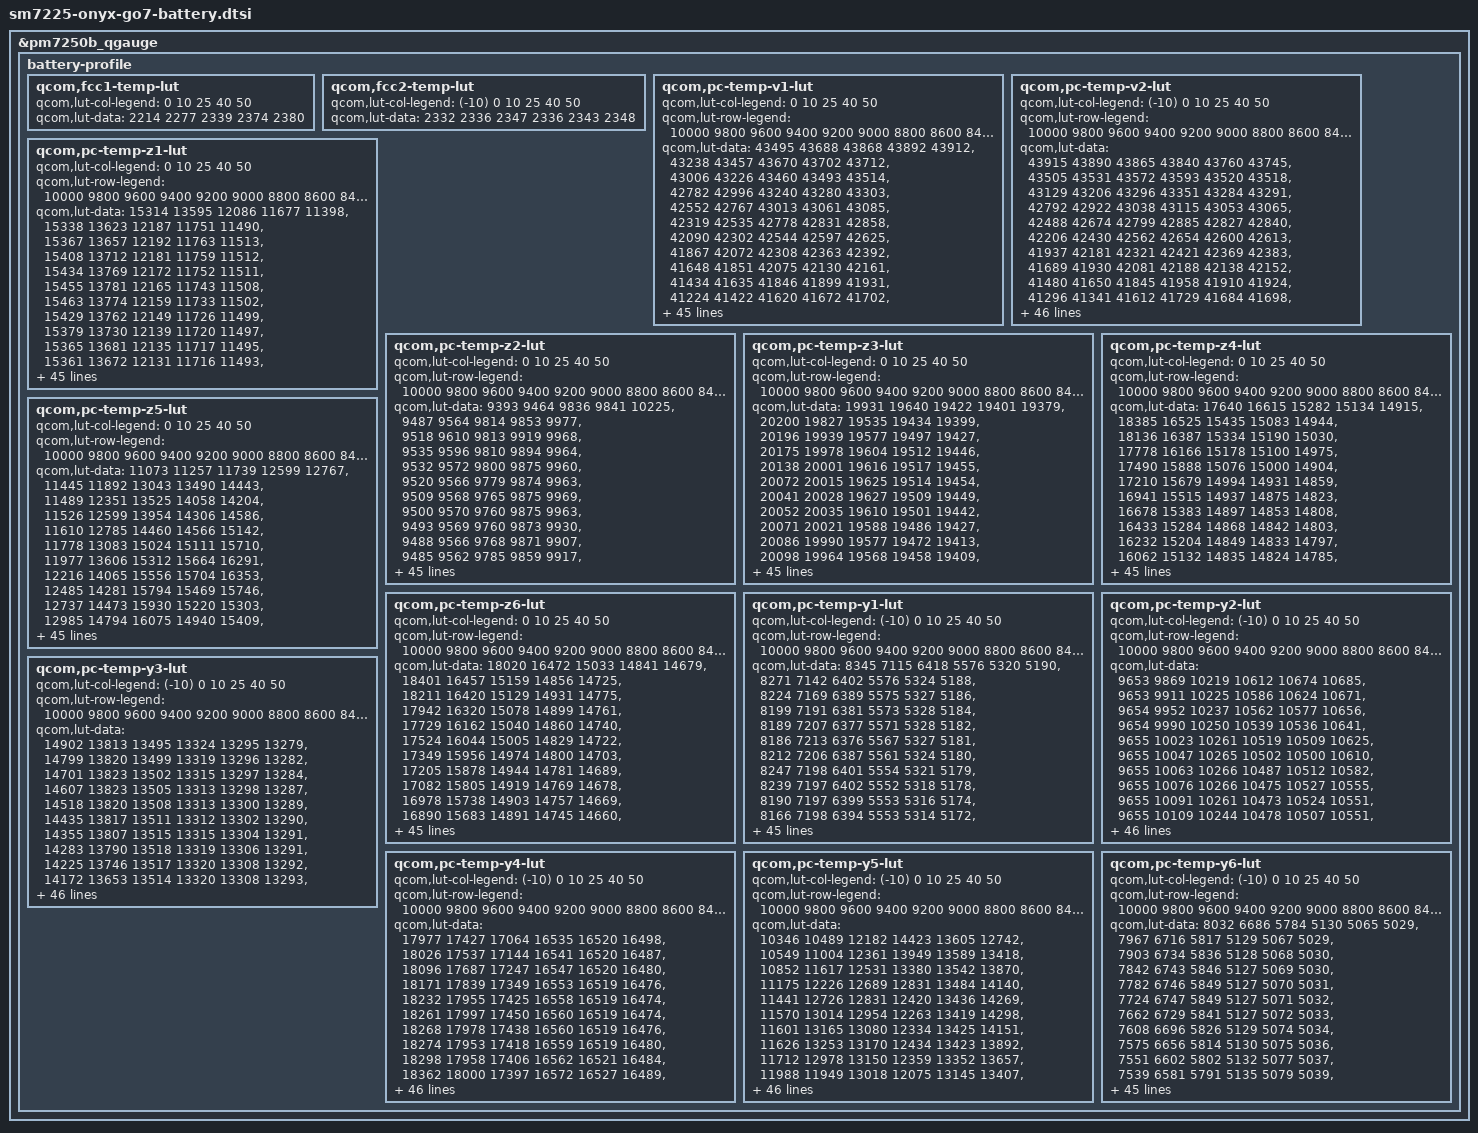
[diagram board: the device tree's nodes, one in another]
// SPDX-License-Identifier: BSD-3-Clause

&pm7250b_qgauge {
	battery-profile {
		qcom,fcc1-temp-lut {
			qcom,lut-col-legend = <0 10 25 40 50>;
			qcom,lut-data = <2214 2277 2339 2374 2380>;
		};

		qcom,fcc2-temp-lut {
			qcom,lut-col-legend = <(-10) 0 10 25 40 50>;
			qcom,lut-data = <2332 2336 2347 2336 2343 2348>;
		};

		qcom,pc-temp-v1-lut {
			qcom,lut-col-legend = <0 10 25 40 50>;
			qcom,lut-row-legend = <10000 9800 9600 9400 9200 9000 8800 8600 8400 8200
						8000 7800 7600 7400 7200 7000 6800 6600 6400 6200
						6000 5800 5600 5400 5200 5000 4800 4600 4400 4200
						4000 3800 3600 3400 3200 3000 2800 2600 2400 2200
						2000 1800 1600 1400 1200 1000 900 800 700 600 500
						400 300 200 100 0>;
			qcom,lut-data = <43495 43688 43868 43892 43912>,
					<43238 43457 43670 43702 43712>,
					<43006 43226 43460 43493 43514>,
					<42782 42996 43240 43280 43303>,
					<42552 42767 43013 43061 43085>,
					<42319 42535 42778 42831 42858>,
					<42090 42302 42544 42597 42625>,
					<41867 42072 42308 42363 42392>,
					<41648 41851 42075 42130 42161>,
					<41434 41635 41846 41899 41931>,
					<41224 41422 41620 41672 41702>,
					<41020 41211 41400 41449 41476>,
					<40825 41005 41183 41229 41256>,
					<40637 40810 40975 41015 41042>,
					<40450 40621 40773 40808 40834>,
					<40258 40434 40578 40608 40631>,
					<40078 40250 40393 40416 40436>,
					<39922 40074 40217 40235 40252>,
					<39783 39914 40046 40062 40076>,
					<39649 39765 39885 39889 39902>,
					<39520 39614 39721 39723 39733>,
					<39396 39461 39510 39542 39554>,
					<39273 39300 39219 39305 39331>,
					<39152 39098 38991 39065 39097>,
					<39035 38868 38873 38907 38927>,
					<38920 38706 38784 38792 38798>,
					<38809 38604 38687 38686 38684>,
					<38704 38528 38587 38580 38577>,
					<38603 38475 38495 38484 38480>,
					<38512 38435 38410 38396 38389>,
					<38440 38396 38334 38318 38305>,
					<38378 38357 38266 38249 38229>,
					<38329 38319 38205 38190 38161>,
					<38293 38284 38151 38134 38098>,
					<38262 38252 38106 38082 38040>,
					<38230 38217 38063 38031 37984>,
					<38200 38182 38021 37976 37919>,
					<38162 38140 37979 37916 37845>,
					<38105 38072 37921 37845 37763>,
					<38028 37962 37830 37758 37677>,
					<37929 37840 37720 37655 37579>,
					<37785 37717 37604 37537 37465>,
					<37633 37580 37471 37400 37329>,
					<37474 37417 37309 37241 37172>,
					<37358 37271 37165 37098 37032>,
					<37254 37178 37077 37016 36954>,
					<37214 37147 37056 36996 36933>,
					<37178 37124 37039 36979 36919>,
					<37142 37101 37018 36960 36901>,
					<37089 37057 36976 36901 36841>,
					<36920 36868 36756 36649 36557>,
					<36502 36446 36340 36241 36140>,
					<35943 35891 35782 35691 35591>,
					<35188 35137 35024 34942 34832>,
					<33993 33976 33864 33801 33677>,
					<30000 30000 30000 30000 30000>;
		};

		qcom,pc-temp-v2-lut {
			qcom,lut-col-legend = <(-10) 0 10 25 40 50>;
			qcom,lut-row-legend = <10000 9800 9600 9400 9200 9000 8800 8600 8400 8200
						8000 7800 7600 7400 7200 7000 6800 6600 6400 6200
						6000 5800 5600 5400 5200 5000 4800 4600 4400 4200
						4000 3800 3600 3400 3200 3000 2800 2600 2400 2200
						2000 1800 1600 1400 1200 1000 900 800 700 600 500
						400 300 200 100 0>;
			qcom,lut-data = <43915 43890 43865 43840 43760 43745>,
					<43505 43531 43572 43593 43520 43518>,
					<43129 43206 43296 43351 43284 43291>,
					<42792 42922 43038 43115 43053 43065>,
					<42488 42674 42799 42885 42827 42840>,
					<42206 42430 42562 42654 42600 42613>,
					<41937 42181 42321 42421 42369 42383>,
					<41689 41930 42081 42188 42138 42152>,
					<41480 41650 41845 41958 41910 41924>,
					<41296 41341 41612 41729 41684 41698>,
					<41131 41136 41381 41505 41462 41475>,
					<40997 41050 41140 41288 41244 41256>,
					<40850 40968 40918 41074 41029 41040>,
					<40569 40769 40746 40865 40824 40834>,
					<40122 40423 40601 40660 40624 40633>,
					<39792 40123 40430 40464 40430 40439>,
					<39609 39897 40221 40277 40242 40251>,
					<39450 39686 39996 40095 40060 40068>,
					<39252 39463 39755 39922 39888 39897>,
					<39040 39239 39505 39754 39721 39730>,
					<38844 39034 39279 39555 39521 39529>,
					<38656 38849 39074 39291 39255 39272>,
					<38499 38673 38888 39045 39018 39041>,
					<38391 38483 38725 38873 38859 38880>,
					<38309 38301 38577 38732 38729 38746>,
					<38235 38192 38439 38608 38610 38625>,
					<38172 38128 38309 38496 38501 38516>,
					<38111 38076 38193 38395 38401 38415>,
					<38051 38027 38082 38301 38309 38322>,
					<37992 37984 37987 38214 38224 38234>,
					<37933 37938 37926 38135 38147 38156>,
					<37874 37890 37882 38062 38076 38083>,
					<37813 37841 37841 37992 38005 38011>,
					<37747 37792 37801 37926 37935 37943>,
					<37677 37742 37761 37863 37860 37870>,
					<37607 37688 37716 37792 37770 37769>,
					<37537 37630 37668 37717 37664 37644>,
					<37466 37567 37611 37638 37563 37531>,
					<37392 37498 37539 37561 37474 37436>,
					<37317 37419 37455 37481 37384 37343>,
					<37246 37324 37353 37389 37290 37248>,
					<37178 37211 37233 37285 37189 37146>,
					<37105 37086 37085 37169 37065 37026>,
					<37028 36960 36936 37032 36926 36885>,
					<36943 36857 36819 36901 36836 36802>,
					<36843 36782 36738 36869 36819 36782>,
					<36784 36748 36706 36854 36802 36765>,
					<36715 36718 36670 36838 36776 36744>,
					<36620 36673 36611 36805 36711 36682>,
					<36472 36568 36487 36703 36494 36472>,
					<36207 36300 36219 36410 36113 36092>,
					<35795 35835 35764 35942 35615 35591>,
					<35187 35197 35136 35326 34964 34942>,
					<34322 34323 34257 34512 34110 34081>,
					<33006 32950 32909 33355 32852 32869>,
					<30300 30329 30466 30054 30346 30226>;
		};

		qcom,pc-temp-z1-lut {
			qcom,lut-col-legend = <0 10 25 40 50>;
			qcom,lut-row-legend = <10000 9800 9600 9400 9200 9000 8800 8600 8400 8200
						8000 7800 7600 7400 7200 7000 6800 6600 6400 6200
						6000 5800 5600 5400 5200 5000 4800 4600 4400 4200
						4000 3800 3600 3400 3200 3000 2800 2600 2400 2200
						2000 1800 1600 1400 1200 1000 900 800 700 600 500
						400 300 200 100 0>;
			qcom,lut-data = <15314 13595 12086 11677 11398>,
					<15338 13623 12187 11751 11490>,
					<15367 13657 12192 11763 11513>,
					<15408 13712 12181 11759 11512>,
					<15434 13769 12172 11752 11511>,
					<15455 13781 12165 11743 11508>,
					<15463 13774 12159 11733 11502>,
					<15429 13762 12149 11726 11499>,
					<15379 13730 12139 11720 11497>,
					<15365 13681 12135 11717 11495>,
					<15361 13672 12131 11716 11493>,
					<15352 13701 12131 11716 11492>,
					<15327 13727 12134 11714 11491>,
					<15293 13716 12137 11712 11491>,
					<15263 13692 12135 11711 11492>,
					<15238 13688 12131 11712 11494>,
					<15211 13727 12130 11714 11496>,
					<15161 13762 12132 11716 11496>,
					<15087 13756 12135 11719 11496>,
					<15051 13740 12141 11722 11497>,
					<15065 13735 12151 11724 11499>,
					<15091 13749 12157 11727 11502>,
					<15111 13766 12162 11732 11505>,
					<15135 13770 12168 11739 11509>,
					<15158 13766 12178 11744 11512>,
					<15181 13769 12188 11749 11516>,
					<15203 13796 12196 11754 11520>,
					<15210 13822 12203 11763 11525>,
					<15210 13823 12210 11772 11531>,
					<15209 13819 12228 11777 11536>,
					<15201 13816 12245 11782 11541>,
					<15179 13828 12246 11786 11546>,
					<15168 13846 12241 11791 11550>,
					<15164 13857 12239 11796 11555>,
					<15164 13871 12247 11805 11560>,
					<15197 13881 12258 11815 11566>,
					<15300 13883 12267 11820 11570>,
					<15372 13883 12277 11822 11573>,
					<15377 13891 12288 11825 11576>,
					<15367 13910 12302 11830 11579>,
					<15342 13924 12313 11835 11582>,
					<15266 13948 12313 11841 11586>,
					<15247 13965 12310 11847 11590>,
					<15343 13948 12315 11854 11593>,
					<15307 13921 12329 11864 11599>,
					<15201 13940 12333 11880 11604>,
					<15247 13944 12351 11884 11606>,
					<15301 13924 12343 11886 11608>,
					<15208 13909 12338 11890 11610>,
					<15211 13964 12363 11893 11614>,
					<15228 13944 12378 11898 11621>,
					<15216 13980 12379 11909 11630>,
					<15258 14028 12400 11927 11641>,
					<15295 14050 12450 11948 11660>,
					<15295 14050 12450 11948 11660>,
					<15295 14050 12450 11948 11660>;
		};

		qcom,pc-temp-z2-lut {
			qcom,lut-col-legend = <0 10 25 40 50>;
			qcom,lut-row-legend = <10000 9800 9600 9400 9200 9000 8800 8600 8400 8200
						8000 7800 7600 7400 7200 7000 6800 6600 6400 6200
						6000 5800 5600 5400 5200 5000 4800 4600 4400 4200
						4000 3800 3600 3400 3200 3000 2800 2600 2400 2200
						2000 1800 1600 1400 1200 1000 900 800 700 600 500
						400 300 200 100 0>;
			qcom,lut-data = <9393 9464 9836 9841 10225>,
					<9487 9564 9814 9853 9977>,
					<9518 9610 9813 9919 9968>,
					<9535 9596 9810 9894 9964>,
					<9532 9572 9800 9875 9960>,
					<9520 9566 9779 9874 9963>,
					<9509 9568 9765 9875 9969>,
					<9500 9570 9760 9875 9963>,
					<9493 9569 9760 9873 9930>,
					<9488 9566 9768 9871 9907>,
					<9485 9562 9785 9859 9917>,
					<9482 9555 9795 9846 9937>,
					<9480 9548 9802 9843 9945>,
					<9477 9543 9808 9842 9956>,
					<9474 9539 9817 9846 9965>,
					<9468 9538 9828 9854 9978>,
					<9463 9543 9835 9863 9990>,
					<9465 9551 9841 9876 9993>,
					<9469 9563 9845 9893 9991>,
					<9472 9580 9829 9899 9989>,
					<9467 9598 9804 9902 9987>,
					<9462 9616 9803 9902 9987>,
					<9461 9631 9822 9879 9988>,
					<9463 9638 9835 9850 9990>,
					<9466 9642 9837 9866 10001>,
					<9469 9648 9838 9937 10038>,
					<9475 9657 9836 9968 10057>,
					<9481 9665 9828 9941 9993>,
					<9491 9666 9820 9911 9915>,
					<9501 9666 9811 9907 9911>,
					<9505 9667 9804 9907 9921>,
					<9509 9672 9808 9909 9929>,
					<9511 9678 9829 9914 9936>,
					<9511 9683 9847 9921 9946>,
					<9512 9687 9864 9946 9973>,
					<9514 9691 9878 9984 10021>,
					<9517 9696 9882 10006 10049>,
					<9521 9702 9884 10020 10082>,
					<9535 9708 9889 10029 10097>,
					<9555 9715 9908 10033 10119>,
					<9570 9718 9923 10036 10147>,
					<9579 9711 9918 10029 10130>,
					<9589 9705 9912 10007 10085>,
					<9601 9707 9908 9994 10075>,
					<9303 9738 9914 9985 10080>,
					<9226 9745 9899 9998 10106>,
					<9240 9744 9898 9968 10072>,
					<9257 9701 9919 9957 10076>,
					<9277 9674 9936 9991 10105>,
					<9260 9683 9889 9994 10135>,
					<9253 9688 9964 9948 10023>,
					<9213 9602 9946 9922 9984>,
					<9159 9555 9899 9913 9953>,
					<9106 9494 9877 9861 9899>,
					<9106 9494 9877 9861 9899>,
					<9106 9494 9877 9861 9899>;
		};

		qcom,pc-temp-z3-lut {
			qcom,lut-col-legend = <0 10 25 40 50>;
			qcom,lut-row-legend = <10000 9800 9600 9400 9200 9000 8800 8600 8400 8200
						8000 7800 7600 7400 7200 7000 6800 6600 6400 6200
						6000 5800 5600 5400 5200 5000 4800 4600 4400 4200
						4000 3800 3600 3400 3200 3000 2800 2600 2400 2200
						2000 1800 1600 1400 1200 1000 900 800 700 600 500
						400 300 200 100 0>;
			qcom,lut-data = <19931 19640 19422 19401 19379>,
					<20200 19827 19535 19434 19399>,
					<20196 19939 19577 19497 19427>,
					<20175 19978 19604 19512 19446>,
					<20138 20001 19616 19517 19455>,
					<20072 20015 19625 19514 19454>,
					<20041 20028 19627 19509 19449>,
					<20052 20035 19610 19501 19442>,
					<20071 20021 19588 19486 19427>,
					<20086 19990 19577 19472 19413>,
					<20098 19964 19568 19458 19409>,
					<20106 19942 19560 19447 19405>,
					<20109 19924 19549 19442 19397>,
					<20110 19912 19540 19438 19384>,
					<20110 19900 19533 19435 19378>,
					<20109 19886 19526 19432 19378>,
					<20106 19863 19521 19430 19377>,
					<20097 19841 19511 19427 19376>,
					<20077 19833 19504 19425 19375>,
					<20069 19826 19506 19425 19375>,
					<20073 19823 19511 19426 19380>,
					<20081 19818 19520 19426 19385>,
					<20092 19815 19539 19425 19381>,
					<20118 19821 19550 19422 19375>,
					<20142 19835 19534 19425 19381>,
					<20159 19841 19512 19436 19414>,
					<20174 19838 19514 19450 19432>,
					<20177 19833 19542 19472 19427>,
					<20176 19825 19559 19490 19419>,
					<20174 19815 19560 19489 19413>,
					<20169 19807 19561 19483 19407>,
					<20158 19803 19559 19475 19401>,
					<20144 19800 19552 19463 19395>,
					<20127 19798 19546 19453 19390>,
					<20106 19795 19540 19449 19388>,
					<20082 19792 19535 19446 19387>,
					<20052 19784 19532 19445 19386>,
					<20022 19774 19529 19443 19386>,
					<19990 19768 19526 19442 19385>,
					<19959 19762 19523 19440 19385>,
					<19944 19758 19518 19436 19384>,
					<19938 19753 19513 19433 19383>,
					<19926 19745 19507 19429 19382>,
					<19891 19726 19503 19425 19380>,
					<19404 19674 19489 19417 19373>,
					<19289 19619 19472 19405 19361>,
					<19286 19609 19461 19405 19362>,
					<19284 19530 19452 19398 19356>,
					<19280 19444 19450 19392 19352>,
					<19282 19429 19452 19391 19359>,
					<19283 19469 19445 19419 19387>,
					<19289 19439 19445 19413 19390>,
					<19302 19422 19435 19419 19387>,
					<19343 19430 19438 19418 19392>,
					<19343 19430 19438 19418 19392>,
					<19343 19430 19438 19418 19392>;
		};

		qcom,pc-temp-z4-lut {
			qcom,lut-col-legend = <0 10 25 40 50>;
			qcom,lut-row-legend = <10000 9800 9600 9400 9200 9000 8800 8600 8400 8200
						8000 7800 7600 7400 7200 7000 6800 6600 6400 6200
						6000 5800 5600 5400 5200 5000 4800 4600 4400 4200
						4000 3800 3600 3400 3200 3000 2800 2600 2400 2200
						2000 1800 1600 1400 1200 1000 900 800 700 600 500
						400 300 200 100 0>;
			qcom,lut-data = <17640 16615 15282 15134 14915>,
					<18385 16525 15435 15083 14944>,
					<18136 16387 15334 15190 15030>,
					<17778 16166 15178 15100 14975>,
					<17490 15888 15076 15000 14904>,
					<17210 15679 14994 14931 14859>,
					<16941 15515 14937 14875 14823>,
					<16678 15383 14897 14853 14808>,
					<16433 15284 14868 14842 14803>,
					<16232 15204 14849 14833 14797>,
					<16062 15132 14835 14824 14785>,
					<15917 15062 14824 14815 14771>,
					<15793 15009 14814 14804 14762>,
					<15687 14977 14807 14791 14755>,
					<15604 14953 14799 14778 14748>,
					<15545 14945 14790 14767 14735>,
					<15489 14943 14785 14757 14722>,
					<15418 14941 14782 14747 14711>,
					<15338 14924 14780 14738 14700>,
					<15274 14889 14778 14737 14698>,
					<15232 14878 14776 14744 14703>,
					<15195 14885 14801 14758 14712>,
					<15153 14902 14954 14859 14790>,
					<15106 14971 15054 14988 14911>,
					<15070 15115 15039 14996 14922>,
					<15049 15171 15007 14958 14868>,
					<15033 15170 14966 14915 14822>,
					<15031 15168 14903 14866 14801>,
					<15043 15155 14857 14824 14785>,
					<15054 15115 14830 14804 14770>,
					<15057 15079 14812 14792 14756>,
					<15059 15051 14806 14787 14746>,
					<15059 15026 14802 14786 14737>,
					<15049 15003 14801 14785 14733>,
					<15031 14981 14804 14788 14735>,
					<15015 14962 14807 14797 14743>,
					<14999 14939 14810 14810 14757>,
					<14981 14921 14813 14830 14784>,
					<14961 14922 14817 14840 14798>,
					<14940 14935 14822 14838 14795>,
					<14929 14941 14825 14833 14788>,
					<14923 14920 14814 14821 14776>,
					<14914 14889 14793 14802 14762>,
					<14893 14869 14783 14795 14763>,
					<15247 14816 14759 14781 14760>,
					<15332 14797 14717 14723 14722>,
					<15319 14791 14710 14713 14700>,
					<15311 14860 14698 14693 14681>,
					<15300 14936 14679 14681 14667>,
					<15287 14940 14692 14695 14679>,
					<15285 14909 14716 14703 14685>,
					<15334 14983 14722 14703 14675>,
					<15375 15017 14733 14692 14670>,
					<15406 15035 14735 14696 14669>,
					<15406 15035 14735 14696 14669>,
					<15406 15035 14735 14696 14669>;
		};

		qcom,pc-temp-z5-lut {
			qcom,lut-col-legend = <0 10 25 40 50>;
			qcom,lut-row-legend = <10000 9800 9600 9400 9200 9000 8800 8600 8400 8200
						8000 7800 7600 7400 7200 7000 6800 6600 6400 6200
						6000 5800 5600 5400 5200 5000 4800 4600 4400 4200
						4000 3800 3600 3400 3200 3000 2800 2600 2400 2200
						2000 1800 1600 1400 1200 1000 900 800 700 600 500
						400 300 200 100 0>;
			qcom,lut-data = <11073 11257 11739 12599 12767>,
					<11445 11892 13043 13490 14443>,
					<11489 12351 13525 14058 14204>,
					<11526 12599 13954 14306 14586>,
					<11610 12785 14460 14566 15142>,
					<11778 13083 15024 15111 15710>,
					<11977 13606 15312 15664 16291>,
					<12216 14065 15556 15704 16353>,
					<12485 14281 15794 15469 15746>,
					<12737 14473 15930 15220 15303>,
					<12985 14794 16075 14940 15409>,
					<13215 15429 16175 14726 15592>,
					<13424 16047 16225 14791 15487>,
					<13614 16575 16234 15051 14995>,
					<13776 17173 16308 15310 14788>,
					<13926 17383 16534 15593 15143>,
					<14040 17244 16611 15927 15719>,
					<14105 17126 16512 16413 16215>,
					<14160 17748 16515 17012 16752>,
					<14222 19450 17123 17423 17551>,
					<14363 21084 18347 18031 19089>,
					<14613 22567 19732 18355 20078>,
					<15076 24198 21678 17492 18052>,
					<16163 26489 22692 16084 14614>,
					<17554 29228 19884 15266 14072>,
					<19281 30103 15715 14574 14677>,
					<21340 28573 15201 14380 15201>,
					<23122 26379 16043 15644 15442>,
					<24945 24650 17139 17515 15700>,
					<26125 22992 18591 19013 16164>,
					<26209 22384 20233 20441 16976>,
					<26152 22370 21654 21331 17883>,
					<26018 22386 23076 21832 18943>,
					<25295 22635 24035 22306 19951>,
					<24156 23423 24817 23072 20833>,
					<23055 24034 25341 23807 21546>,
					<21783 24562 25225 23730 21383>,
					<20891 25198 24717 22617 19881>,
					<20451 25857 24117 21449 18724>,
					<20126 26646 23220 20341 18270>,
					<20221 26990 22391 19455 17964>,
					<21462 26250 21947 19183 17924>,
					<21884 25176 21604 19030 17939>,
					<20339 23480 21051 18287 17152>,
					<12265 22340 20914 17839 16386>,
					<10532 19121 21549 19795 16732>,
					<10509 17909 19917 19994 18257>,
					<10477 15260 18828 20968 19341>,
					<10465 11843 20641 21241 21252>,
					<10465 11699 19461 19768 20197>,
					<10484 12343 16567 21274 22036>,
					<10490 11582 15809 18588 22249>,
					<10415 11262 14742 19081 20803>,
					<10403 11149 14553 18047 21655>,
					<10403 11149 14553 18047 21655>,
					<10403 11149 14553 18047 21655>;
		};

		qcom,pc-temp-z6-lut {
			qcom,lut-col-legend = <0 10 25 40 50>;
			qcom,lut-row-legend = <10000 9800 9600 9400 9200 9000 8800 8600 8400 8200
						8000 7800 7600 7400 7200 7000 6800 6600 6400 6200
						6000 5800 5600 5400 5200 5000 4800 4600 4400 4200
						4000 3800 3600 3400 3200 3000 2800 2600 2400 2200
						2000 1800 1600 1400 1200 1000 900 800 700 600 500
						400 300 200 100 0>;
			qcom,lut-data = <18020 16472 15033 14841 14679>,
					<18401 16457 15159 14856 14725>,
					<18211 16420 15129 14931 14775>,
					<17942 16320 15078 14899 14761>,
					<17729 16162 15040 14860 14740>,
					<17524 16044 15005 14829 14722>,
					<17349 15956 14974 14800 14703>,
					<17205 15878 14944 14781 14689>,
					<17082 15805 14919 14769 14678>,
					<16978 15738 14903 14757 14669>,
					<16890 15683 14891 14745 14660>,
					<16811 15635 14880 14734 14652>,
					<16738 15599 14870 14725 14643>,
					<16671 15578 14862 14717 14634>,
					<16614 15563 14854 14710 14626>,
					<16568 15550 14847 14703 14620>,
					<16525 15540 14841 14698 14615>,
					<16472 15529 14834 14692 14609>,
					<16414 15517 14831 14688 14604>,
					<16386 15505 14832 14688 14603>,
					<16380 15501 14835 14691 14607>,
					<16376 15506 14853 14699 14615>,
					<16376 15516 14931 14743 14649>,
					<16380 15552 14981 14798 14698>,
					<16384 15626 14969 14803 14707>,
					<16390 15656 14948 14795 14701>,
					<16398 15657 14934 14787 14694>,
					<16406 15658 14923 14779 14684>,
					<16418 15652 14914 14771 14673>,
					<16427 15634 14908 14763 14663>,
					<16428 15618 14902 14756 14655>,
					<16429 15607 14897 14750 14648>,
					<16429 15598 14893 14743 14640>,
					<16424 15592 14892 14739 14636>,
					<16414 15587 14892 14740 14637>,
					<16403 15582 14892 14742 14639>,
					<16391 15576 14894 14747 14644>,
					<16378 15570 14897 14756 14657>,
					<16364 15573 14899 14760 14663>,
					<16351 15586 14900 14759 14662>,
					<16348 15592 14901 14757 14659>,
					<16349 15589 14897 14751 14655>,
					<16349 15583 14888 14743 14649>,
					<16330 15576 14884 14739 14648>,
					<16249 15545 14873 14731 14645>,
					<16231 15521 14849 14703 14623>,
					<16225 15515 14843 14698 14615>,
					<16223 15506 14833 14687 14603>,
					<16221 15497 14827 14679 14595>,
					<16226 15501 14836 14686 14600>,
					<16243 15523 14845 14707 14623>,
					<16279 15554 14854 14707 14622>,
					<16324 15580 14860 14710 14622>,
					<16390 15623 14874 14716 14627>,
					<16390 15623 14874 14716 14627>,
					<16390 15623 14874 14716 14627>;
		};

		qcom,pc-temp-y1-lut {
			qcom,lut-col-legend = <(-10) 0 10 25 40 50>;
			qcom,lut-row-legend = <10000 9800 9600 9400 9200 9000 8800 8600 8400 8200
						8000 7800 7600 7400 7200 7000 6800 6600 6400 6200
						6000 5800 5600 5400 5200 5000 4800 4600 4400 4200
						4000 3800 3600 3400 3200 3000 2800 2600 2400 2200
						2000 1800 1600 1400 1200 1000 900 800 700 600 500
						400 300 200 100 0>;
			qcom,lut-data = <8345 7115 6418 5576 5320 5190>,
					<8271 7142 6402 5576 5324 5188>,
					<8224 7169 6389 5575 5327 5186>,
					<8199 7191 6381 5573 5328 5184>,
					<8189 7207 6377 5571 5328 5182>,
					<8186 7213 6376 5567 5327 5181>,
					<8212 7206 6387 5561 5324 5180>,
					<8247 7198 6401 5554 5321 5179>,
					<8239 7197 6402 5552 5318 5178>,
					<8190 7197 6399 5553 5316 5174>,
					<8166 7198 6394 5553 5314 5172>,
					<8202 7202 6385 5551 5309 5169>,
					<8244 7207 6378 5549 5305 5166>,
					<8246 7215 6374 5548 5304 5166>,
					<8235 7233 6367 5548 5303 5166>,
					<8224 7239 6367 5548 5302 5165>,
					<8217 7233 6380 5549 5300 5162>,
					<8214 7226 6394 5550 5299 5160>,
					<8222 7233 6400 5551 5299 5161>,
					<8246 7251 6407 5552 5301 5162>,
					<8254 7255 6413 5552 5302 5163>,
					<8234 7229 6423 5551 5303 5162>,
					<8208 7206 6430 5550 5303 5162>,
					<8187 7218 6426 5553 5304 5164>,
					<8167 7245 6419 5561 5305 5167>,
					<8160 7252 6418 5565 5307 5169>,
					<8156 7248 6420 5569 5312 5169>,
					<8153 7243 6422 5573 5316 5170>,
					<8164 7249 6413 5576 5318 5172>,
					<8186 7261 6401 5581 5321 5175>,
					<8200 7258 6404 5586 5324 5177>,
					<8208 7242 6424 5594 5329 5181>,
					<8211 7226 6434 5601 5333 5184>,
					<8191 7216 6423 5606 5337 5186>,
					<8161 7207 6410 5611 5341 5188>,
					<8161 7199 6407 5617 5345 5191>,
					<8188 7175 6403 5623 5353 5195>,
					<8215 7162 6404 5628 5358 5199>,
					<8242 7179 6424 5633 5360 5202>,
					<8265 7201 6443 5638 5362 5205>,
					<8255 7210 6428 5641 5367 5207>,
					<8202 7221 6404 5645 5373 5209>,
					<8200 7233 6430 5642 5376 5212>,
					<8223 7239 6450 5640 5378 5214>,
					<8251 7230 6469 5652 5379 5213>,
					<8218 7275 6449 5658 5390 5217>,
					<8257 7279 6459 5663 5393 5219>,
					<8223 7266 6452 5663 5388 5220>,
					<8326 7266 6468 5659 5394 5220>,
					<8464 7298 6467 5659 5397 5221>,
					<8513 7329 6481 5679 5400 5226>,
					<8522 7346 6513 5689 5409 5234>,
					<8679 7466 6535 5700 5424 5241>,
					<8955 7545 6666 5732 5446 5254>,
					<8955 7545 6666 5732 5446 5254>,
					<8955 7545 6666 5732 5446 5254>;
		};

		qcom,pc-temp-y2-lut {
			qcom,lut-col-legend = <(-10) 0 10 25 40 50>;
			qcom,lut-row-legend = <10000 9800 9600 9400 9200 9000 8800 8600 8400 8200
						8000 7800 7600 7400 7200 7000 6800 6600 6400 6200
						6000 5800 5600 5400 5200 5000 4800 4600 4400 4200
						4000 3800 3600 3400 3200 3000 2800 2600 2400 2200
						2000 1800 1600 1400 1200 1000 900 800 700 600 500
						400 300 200 100 0>;
			qcom,lut-data = <9653 9869 10219 10612 10674 10685>,
					<9653 9911 10225 10586 10624 10671>,
					<9654 9952 10237 10562 10577 10656>,
					<9654 9990 10250 10539 10536 10641>,
					<9655 10023 10261 10519 10509 10625>,
					<9655 10047 10265 10502 10500 10610>,
					<9655 10063 10266 10487 10512 10582>,
					<9655 10076 10266 10475 10527 10555>,
					<9655 10091 10261 10473 10524 10551>,
					<9655 10109 10244 10478 10507 10551>,
					<9655 10125 10239 10478 10500 10552>,
					<9655 10136 10283 10462 10505 10572>,
					<9656 10150 10341 10447 10511 10597>,
					<9656 10189 10368 10447 10507 10605>,
					<9655 10259 10387 10454 10495 10609>,
					<9655 10270 10412 10464 10491 10610>,
					<9655 9999 10452 10487 10503 10608>,
					<9655 9722 10480 10519 10526 10609>,
					<9655 9691 10471 10556 10587 10635>,
					<9655 9681 10447 10598 10683 10682>,
					<9655 9675 10429 10607 10701 10699>,
					<9654 9670 10416 10585 10633 10705>,
					<9654 9667 10403 10566 10581 10712>,
					<9654 9664 10393 10573 10608 10726>,
					<9654 9662 10382 10590 10659 10744>,
					<9654 9660 10361 10602 10669 10763>,
					<9654 9659 10319 10610 10656 10788>,
					<9654 9657 10287 10616 10648 10805>,
					<9653 9657 10277 10620 10677 10797>,
					<9653 9656 10267 10623 10721 10787>,
					<9653 9655 10216 10629 10730 10814>,
					<9653 9654 10067 10643 10729 10877>,
					<9653 9654 9934 10650 10731 10915>,
					<9653 9653 9837 10638 10756 10912>,
					<9653 9653 9761 10617 10783 10898>,
					<9653 9653 9717 10605 10764 10881>,
					<9653 9652 9686 10593 10698 10843>,
					<9653 9652 9671 10585 10672 10829>,
					<9653 9652 9665 10578 10679 10822>,
					<9652 9652 9661 10569 10689 10812>,
					<9652 9652 9658 10562 10691 10793>,
					<9652 9652 9656 10551 10685 10770>,
					<9652 9652 9655 10544 10653 10775>,
					<9652 9652 9654 10529 10628 10761>,
					<9652 9651 9654 10502 10610 10747>,
					<9651 9651 9653 10491 10622 10721>,
					<9651 9651 9653 10499 10622 10763>,
					<9650 9651 9652 10500 10642 10698>,
					<9650 9651 9652 10499 10622 10688>,
					<9649 9650 9651 10493 10634 10664>,
					<9648 9650 9651 10483 10584 10621>,
					<9647 9649 9650 10455 10557 10614>,
					<9647 9648 9649 10402 10538 10566>,
					<9646 9647 9648 10393 10601 10585>,
					<9646 9647 9648 10393 10601 10585>,
					<9646 9647 9648 10393 10601 10585>;
		};

		qcom,pc-temp-y3-lut {
			qcom,lut-col-legend = <(-10) 0 10 25 40 50>;
			qcom,lut-row-legend = <10000 9800 9600 9400 9200 9000 8800 8600 8400 8200
						8000 7800 7600 7400 7200 7000 6800 6600 6400 6200
						6000 5800 5600 5400 5200 5000 4800 4600 4400 4200
						4000 3800 3600 3400 3200 3000 2800 2600 2400 2200
						2000 1800 1600 1400 1200 1000 900 800 700 600 500
						400 300 200 100 0>;
			qcom,lut-data = <14902 13813 13495 13324 13295 13279>,
					<14799 13820 13499 13319 13296 13282>,
					<14701 13823 13502 13315 13297 13284>,
					<14607 13823 13505 13313 13298 13287>,
					<14518 13820 13508 13313 13300 13289>,
					<14435 13817 13511 13312 13302 13290>,
					<14355 13807 13515 13315 13304 13291>,
					<14283 13790 13518 13319 13306 13291>,
					<14225 13746 13517 13320 13308 13292>,
					<14172 13653 13514 13320 13308 13293>,
					<14152 13611 13508 13321 13309 13293>,
					<14155 13623 13485 13327 13309 13294>,
					<14159 13636 13464 13333 13310 13295>,
					<14134 13632 13467 13333 13312 13297>,
					<14055 13617 13477 13332 13317 13302>,
					<14022 13611 13480 13332 13318 13303>,
					<14034 13613 13475 13334 13315 13301>,
					<14047 13616 13468 13337 13312 13298>,
					<14049 13612 13455 13339 13313 13299>,
					<14049 13606 13437 13342 13317 13302>,
					<14049 13605 13424 13341 13317 13302>,
					<14047 13618 13414 13332 13307 13295>,
					<14046 13630 13407 13322 13298 13288>,
					<14061 13611 13400 13317 13298 13285>,
					<14105 13573 13394 13313 13297 13283>,
					<14152 13567 13390 13312 13297 13282>,
					<14203 13604 13388 13312 13296 13282>,
					<14260 13656 13384 13312 13295 13282>,
					<14318 13715 13377 13313 13296 13282>,
					<14380 13790 13369 13314 13296 13283>,
					<14444 13869 13367 13315 13297 13284>,
					<14512 13954 13366 13317 13298 13285>,
					<14580 14047 13367 13318 13298 13286>,
					<14645 14149 13383 13318 13299 13286>,
					<14709 14257 13410 13318 13299 13286>,
					<14775 14360 13442 13317 13298 13285>,
					<14846 14462 13486 13315 13296 13284>,
					<14912 14550 13534 13314 13293 13283>,
					<14966 14626 13588 13313 13290 13282>,
					<15018 14690 13651 13312 13288 13282>,
					<15075 14734 13730 13311 13290 13281>,
					<15138 14768 13825 13311 13294 13281>,
					<15207 14810 13926 13313 13294 13281>,
					<15286 14852 14036 13316 13292 13281>,
					<15344 14847 13983 13313 13289 13283>,
					<15419 14917 14146 13315 13296 13286>,
					<15581 15016 14267 13317 13298 13286>,
					<15916 15155 14390 13321 13302 13293>,
					<16469 15313 14549 13327 13309 13292>,
					<17257 15503 14713 13330 13309 13293>,
					<18521 15867 14871 13329 13310 13295>,
					<20809 16764 15084 13334 13315 13298>,
					<25011 18451 15603 13340 13321 13304>,
					<33158 21572 16712 13354 13342 13317>,
					<33158 21572 16712 13354 13342 13317>,
					<33158 21572 16712 13354 13342 13317>;
		};

		qcom,pc-temp-y4-lut {
			qcom,lut-col-legend = <(-10) 0 10 25 40 50>;
			qcom,lut-row-legend = <10000 9800 9600 9400 9200 9000 8800 8600 8400 8200
						8000 7800 7600 7400 7200 7000 6800 6600 6400 6200
						6000 5800 5600 5400 5200 5000 4800 4600 4400 4200
						4000 3800 3600 3400 3200 3000 2800 2600 2400 2200
						2000 1800 1600 1400 1200 1000 900 800 700 600 500
						400 300 200 100 0>;
			qcom,lut-data = <17977 17427 17064 16535 16520 16498>,
					<18026 17537 17144 16541 16520 16487>,
					<18096 17687 17247 16547 16520 16480>,
					<18171 17839 17349 16553 16519 16476>,
					<18232 17955 17425 16558 16519 16474>,
					<18261 17997 17450 16560 16519 16474>,
					<18268 17978 17438 16560 16519 16476>,
					<18274 17953 17418 16559 16519 16480>,
					<18298 17958 17406 16562 16521 16484>,
					<18362 18000 17397 16572 16527 16489>,
					<18400 18062 17395 16580 16534 16494>,
					<18407 18223 17423 16585 16543 16501>,
					<18402 18374 17471 16591 16553 16507>,
					<18250 18273 17532 16604 16561 16513>,
					<17798 17922 17607 16628 16570 16518>,
					<17550 17720 17625 16655 16583 16526>,
					<17498 17664 17560 16687 16611 16547>,
					<17455 17616 17462 16723 16647 16574>,
					<17361 17523 17353 16770 16695 16613>,
					<17223 17393 17226 16821 16748 16657>,
					<17125 17267 17124 16824 16748 16655>,
					<17052 17143 17039 16695 16635 16573>,
					<17012 17032 16970 16574 16538 16505>,
					<17011 16934 16919 16550 16521 16492>,
					<17011 16852 16876 16537 16511 16485>,
					<17013 16836 16824 16535 16511 16485>,
					<17015 16850 16764 16537 16518 16490>,
					<17018 16864 16712 16539 16526 16496>,
					<17022 16867 16667 16544 16537 16505>,
					<17027 16870 16635 16553 16550 16517>,
					<17031 16878 16644 16563 16567 16530>,
					<17034 16901 16694 16573 16589 16546>,
					<17037 16924 16744 16582 16602 16560>,
					<17043 16941 16782 16589 16607 16575>,
					<17049 16957 16818 16595 16609 16585>,
					<17052 16971 16856 16590 16595 16571>,
					<17054 16984 16894 16564 16546 16525>,
					<17056 16991 16921 16542 16515 16498>,
					<17068 16993 16942 16529 16503 16486>,
					<17087 16994 16953 16521 16496 16481>,
					<17107 16988 16950 16524 16497 16481>,
					<17128 16963 16940 16537 16501 16484>,
					<17160 16922 16925 16548 16512 16488>,
					<17185 16881 16905 16552 16512 16481>,
					<17158 16859 16857 16521 16496 16462>,
					<17101 16869 16884 16528 16515 16483>,
					<17136 16904 16921 16544 16532 16498>,
					<17225 16951 16986 16570 16550 16511>,
					<17390 17017 17046 16599 16567 16530>,
					<17593 17056 17110 16606 16551 16502>,
					<17881 17080 17146 16596 16568 16510>,
					<18451 17228 17129 16610 16593 16522>,
					<19990 17785 17278 16644 16641 16568>,
					<25838 19834 18109 16751 16797 16692>,
					<25838 19834 18109 16751 16797 16692>,
					<25838 19834 18109 16751 16797 16692>;
		};

		qcom,pc-temp-y5-lut {
			qcom,lut-col-legend = <(-10) 0 10 25 40 50>;
			qcom,lut-row-legend = <10000 9800 9600 9400 9200 9000 8800 8600 8400 8200
						8000 7800 7600 7400 7200 7000 6800 6600 6400 6200
						6000 5800 5600 5400 5200 5000 4800 4600 4400 4200
						4000 3800 3600 3400 3200 3000 2800 2600 2400 2200
						2000 1800 1600 1400 1200 1000 900 800 700 600 500
						400 300 200 100 0>;
			qcom,lut-data = <10346 10489 12182 14423 13605 12742>,
					<10549 11004 12361 13949 13589 13418>,
					<10852 11617 12531 13380 13542 13870>,
					<11175 12226 12689 12831 13484 14140>,
					<11441 12726 12831 12420 13436 14269>,
					<11570 13014 12954 12263 13419 14298>,
					<11601 13165 13080 12334 13425 14151>,
					<11626 13253 13170 12434 13423 13892>,
					<11712 12978 13150 12359 13352 13657>,
					<11988 11949 13018 12075 13145 13407>,
					<12442 11490 12806 11946 12911 13150>,
					<14093 12623 12182 12169 12604 12823>,
					<15782 14037 11624 12424 12372 12594>,
					<15277 14467 11998 12297 12431 12744>,
					<13217 14704 13181 11859 12627 13152>,
					<12383 14753 14113 11686 12659 13233>,
					<13229 14499 14836 11745 12131 12572>,
					<14107 14252 15301 11873 11650 11998>,
					<14107 14301 15423 12428 11881 12072>,
					<13905 14515 15491 13657 12556 12341>,
					<13548 14893 15597 14569 13219 12826>,
					<12284 15994 15761 15270 13940 14045>,
					<11143 16843 15926 15653 14544 14849>,
					<10946 15266 16061 15315 14971 14618>,
					<10850 11972 16220 14628 15289 14166>,
					<10840 11002 16576 14435 15239 13882>,
					<10926 10926 17385 14539 14636 13619>,
					<11034 10898 17797 14643 14205 13476>,
					<11110 11080 16037 14825 14268 13438>,
					<11182 11396 13461 15159 14420 13451>,
					<11278 11468 12468 15453 14480 13588>,
					<11438 11465 11885 16122 14681 13862>,
					<11535 11466 11703 16624 14908 14115>,
					<11485 11560 11887 17000 15510 14387>,
					<11392 11729 12153 17393 16180 14660>,
					<11363 11863 12404 17400 16399 14973>,
					<11356 12004 12757 17069 16550 15484>,
					<11345 12085 12967 16713 16503 15722>,
					<11207 12185 13164 16216 15305 15619>,
					<11019 12295 13297 15564 14080 15377>,
					<11000 12246 13203 14842 14435 14852>,
					<11039 12031 12993 14124 15304 14147>,
					<11068 11858 12488 14309 14519 13783>,
					<11111 11661 12042 14587 13936 14548>,
					<11295 11398 11895 14918 13644 16072>,
					<11405 11315 11814 14908 14116 14397>,
					<11401 11258 11754 14558 13562 13299>,
					<11309 11383 11648 14330 13442 14302>,
					<11059 11528 11882 14043 13949 13676>,
					<10801 11644 12463 14262 16100 16067>,
					<10297 11398 12758 15126 15481 16033>,
					<9828 10709 12510 15784 15674 16872>,
					<9379 10120 11611 15863 15737 17446>,
					<9081 9561 10498 15874 15406 16538>,
					<9081 9561 10498 15874 15406 16538>,
					<9081 9561 10498 15874 15406 16538>;
		};

		qcom,pc-temp-y6-lut {
			qcom,lut-col-legend = <(-10) 0 10 25 40 50>;
			qcom,lut-row-legend = <10000 9800 9600 9400 9200 9000 8800 8600 8400 8200
						8000 7800 7600 7400 7200 7000 6800 6600 6400 6200
						6000 5800 5600 5400 5200 5000 4800 4600 4400 4200
						4000 3800 3600 3400 3200 3000 2800 2600 2400 2200
						2000 1800 1600 1400 1200 1000 900 800 700 600 500
						400 300 200 100 0>;
			qcom,lut-data = <8032 6686 5784 5130 5065 5029>,
					<7967 6716 5817 5129 5067 5029>,
					<7903 6734 5836 5128 5068 5030>,
					<7842 6743 5846 5127 5069 5030>,
					<7782 6746 5849 5127 5070 5031>,
					<7724 6747 5849 5127 5071 5032>,
					<7662 6729 5841 5127 5072 5033>,
					<7608 6696 5826 5129 5074 5034>,
					<7575 6656 5814 5130 5075 5036>,
					<7551 6602 5802 5132 5077 5037>,
					<7539 6581 5791 5135 5079 5039>,
					<7536 6633 5780 5139 5081 5041>,
					<7534 6692 5773 5144 5084 5043>,
					<7472 6668 5783 5149 5088 5047>,
					<7292 6572 5811 5154 5092 5051>,
					<7206 6505 5819 5161 5098 5055>,
					<7196 6474 5797 5172 5104 5059>,
					<7189 6448 5764 5184 5111 5065>,
					<7168 6416 5725 5199 5125 5076>,
					<7134 6382 5678 5215 5143 5091>,
					<7111 6359 5644 5215 5143 5090>,
					<7097 6346 5618 5172 5103 5061>,
					<7089 6334 5600 5130 5069 5036>,
					<7101 6318 5589 5120 5064 5030>,
					<7138 6303 5580 5114 5061 5027>,
					<7176 6305 5573 5113 5061 5026>,
					<7217 6358 5565 5115 5062 5028>,
					<7262 6428 5561 5118 5064 5030>,
					<7307 6491 5562 5121 5068 5033>,
					<7354 6561 5564 5125 5073 5037>,
					<7405 6637 5575 5130 5079 5041>,
					<7461 6719 5616 5136 5086 5047>,
					<7518 6806 5664 5141 5091 5052>,
					<7572 6898 5719 5145 5094 5057>,
					<7625 6992 5785 5147 5095 5060>,
					<7679 7081 5858 5146 5091 5055>,
					<7734 7165 5944 5139 5077 5042>,
					<7787 7238 6035 5134 5067 5034>,
					<7836 7302 6133 5132 5062 5030>,
					<7883 7354 6235 5130 5059 5029>,
					<7936 7387 6336 5131 5061 5029>,
					<7992 7411 6438 5137 5066 5030>,
					<8066 7437 6538 5145 5069 5031>,
					<8152 7466 6639 5150 5069 5029>,
					<8201 7464 6591 5141 5063 5025>,
					<8263 7524 6734 5145 5074 5034>,
					<8413 7623 6848 5152 5081 5039>,
					<8742 7748 6972 5164 5090 5047>,
					<9289 7893 7125 5178 5099 5053>,
					<10037 8062 7281 5184 5096 5045>,
					<11167 8387 7425 5183 5103 5050>,
					<13143 9211 7605 5194 5115 5056>,
					<16764 10737 8117 5215 5136 5074>,
					<24046 13604 9307 5264 5199 5122>,
					<24046 13604 9307 5264 5199 5122>,
					<24046 13604 9307 5264 5199 5122>;
		};
	};
};
